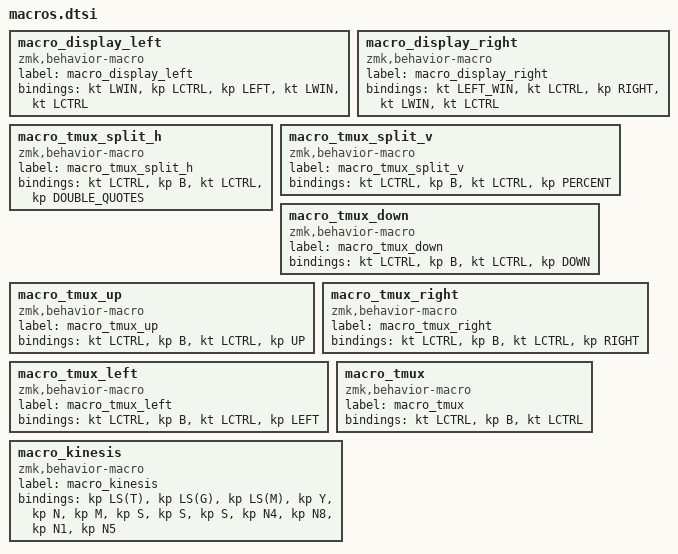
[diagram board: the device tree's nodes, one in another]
macro_display_left: macro_display_left{
compatible = "zmk,behavior-macro";
label = "macro_display_left";
#binding-cells = <0>;
bindings = <&kt LWIN>, <&kp LCTRL>, <&kp LEFT>, <&kt LWIN>, <&kt LCTRL>;
};
macro_display_right: macro_display_right{
compatible = "zmk,behavior-macro";
label = "macro_display_right";
#binding-cells = <0>;
bindings = <&kt LEFT_WIN>, <&kt LCTRL>, <&kp RIGHT>, <&kt LWIN>, <&kt LCTRL>;
};
macro_tmux_split_h: macro_tmux_split_h{
compatible = "zmk,behavior-macro";
label = "macro_tmux_split_h";
#binding-cells = <0>;
bindings = <&kt LCTRL>, <&kp B>, <&kt LCTRL>, <&kp DOUBLE_QUOTES>;
};
macro_tmux_split_v: macro_tmux_split_v{
compatible = "zmk,behavior-macro";
label = "macro_tmux_split_v";
#binding-cells = <0>;
bindings = <&kt LCTRL>, <&kp B>, <&kt LCTRL>, <&kp PERCENT>;
};
macro_tmux_down: macro_tmux_down{
compatible = "zmk,behavior-macro";
label = "macro_tmux_down";
#binding-cells = <0>;
bindings = <&kt LCTRL>, <&kp B>, <&kt LCTRL>, <&kp DOWN>;
};
macro_tmux_up: macro_tmux_up{
compatible = "zmk,behavior-macro";
label = "macro_tmux_up";
#binding-cells = <0>;
bindings = <&kt LCTRL>, <&kp B>, <&kt LCTRL>, <&kp UP>;
};
macro_tmux_right: macro_tmux_right{
compatible = "zmk,behavior-macro";
label = "macro_tmux_right";
#binding-cells = <0>;
bindings = <&kt LCTRL>, <&kp B>, <&kt LCTRL>, <&kp RIGHT>;
};
macro_tmux_left: macro_tmux_left{
compatible = "zmk,behavior-macro";
label = "macro_tmux_left";
#binding-cells = <0>;
bindings = <&kt LCTRL>, <&kp B>, <&kt LCTRL>, <&kp LEFT>;
};
macro_tmux: macro_tmux{
compatible = "zmk,behavior-macro";
label = "macro_tmux";
#binding-cells = <0>;
bindings = <&kt LCTRL>, <&kp B>, <&kt LCTRL>;
};
macro_kinesis: macro_kinesis{
compatible = "zmk,behavior-macro";
label = "macro_kinesis";
#binding-cells = <0>;
bindings = <&kp LS(T)>, <&kp LS(G)>, <&kp LS(M)>, <&kp Y>, <&kp N>, <&kp M>, <&kp S>, <&kp S>, <&kp S>, <&kp N4>, <&kp N8>, <&kp N1>, <&kp N5>;
};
